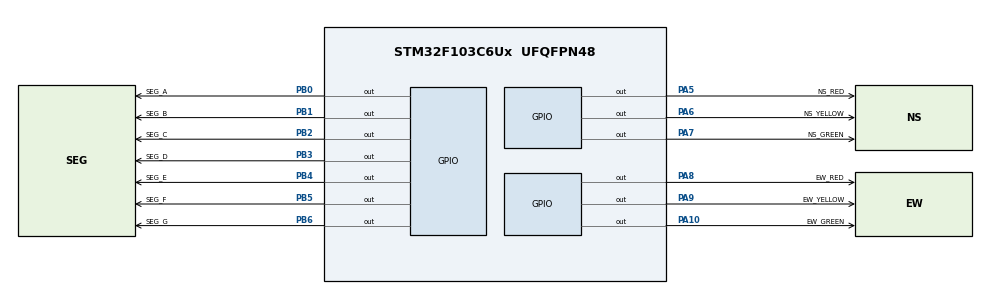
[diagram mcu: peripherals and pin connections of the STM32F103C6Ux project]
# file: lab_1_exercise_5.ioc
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Mcu.Family=STM32F1
Mcu.Name=STM32F103C6Ux
Mcu.Package=UFQFPN48
NVIC.PriorityGroup=NVIC_PRIORITYGROUP_4
ProjectManager.HeapSize=0x200
ProjectManager.StackSize=0x400
ProjectManager.TargetToolchain=STM32CubeIDE
RCC.APB1Freq_Value=8000000
RCC.APB2Freq_Value=8000000
VP_SYS_VS_ND.Mode=No_Debug
board=custom
PA5.GPIO_Label=NS_RED
PA5.PinState=GPIO_PIN_SET
PA5.Signal=GPIO_Output
PA6.GPIO_Label=NS_YELLOW
PA6.PinState=GPIO_PIN_SET
PA6.Signal=GPIO_Output
PA7.GPIO_Label=NS_GREEN
PA7.PinState=GPIO_PIN_SET
PA7.Signal=GPIO_Output
PA8.GPIO_Label=EW_RED
PA8.PinState=GPIO_PIN_SET
PA8.Signal=GPIO_Output
PA9.GPIO_Label=EW_YELLOW
PA9.PinState=GPIO_PIN_SET
PA9.Signal=GPIO_Output
PA10.GPIO_Label=EW_GREEN
PA10.PinState=GPIO_PIN_SET
PA10.Signal=GPIO_Output
PB0.GPIO_Label=SEG_A
PB0.PinState=GPIO_PIN_SET
PB0.Signal=GPIO_Output
PB1.GPIO_Label=SEG_B
PB1.PinState=GPIO_PIN_SET
PB1.Signal=GPIO_Output
PB2.GPIO_Label=SEG_C
PB2.PinState=GPIO_PIN_SET
PB2.Signal=GPIO_Output
PB3.GPIO_Label=SEG_D
PB3.PinState=GPIO_PIN_SET
PB3.Signal=GPIO_Output
PB4.GPIO_Label=SEG_E
PB4.PinState=GPIO_PIN_SET
PB4.Signal=GPIO_Output
PB5.GPIO_Label=SEG_F
PB5.PinState=GPIO_PIN_SET
PB5.Signal=GPIO_Output
PB6.GPIO_Label=SEG_G
PB6.PinState=GPIO_PIN_SET
PB6.Signal=GPIO_Output

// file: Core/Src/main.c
/* USER CODE BEGIN Header */
/**
  ******************************************************************************
  * @file           : main.c
  * @brief          : Main program body
  ******************************************************************************
  * @attention
  *
  * <h2><center>&copy; Copyright (c) 2026 STMicroelectronics.
  * All rights reserved.</center></h2>
  *
  * This software component is licensed by ST under BSD 3-Clause license,
  * the "License"; You may not use this file except in compliance with the
  * License. You may obtain a copy of the License at:
  *                        opensource.org/licenses/BSD-3-Clause
  *
  ******************************************************************************
  */
/* USER CODE END Header */
#include "main.h"

/* USER CODE BEGIN Includes */
#include "lab_app.h"

/* USER CODE END Includes */

void SystemClock_Config(void);
static void MX_GPIO_Init(void);

int main(void)
{

  /* MCU Configuration--------------------------------------------------------*/

  /* Reset of all peripherals, Initializes the Flash interface and the Systick. */
  HAL_Init();

  /* Configure the system clock */
  SystemClock_Config();

  /* Initialize all configured peripherals */
  MX_GPIO_Init();

  /* Infinite loop */
  while (1)
  {
    /* USER CODE BEGIN 3 */
    runExercise();
  }
  /* USER CODE END 3 */
}

void SystemClock_Config(void)
{
  RCC_OscInitTypeDef RCC_OscInitStruct = {0};
  RCC_ClkInitTypeDef RCC_ClkInitStruct = {0};

  /** Initializes the RCC Oscillators according to the specified parameters
  * in the RCC_OscInitTypeDef structure.
  */
  RCC_OscInitStruct.OscillatorType = RCC_OSCILLATORTYPE_HSI;
  RCC_OscInitStruct.HSIState = RCC_HSI_ON;
  RCC_OscInitStruct.HSICalibrationValue = RCC_HSICALIBRATION_DEFAULT;
  RCC_OscInitStruct.PLL.PLLState = RCC_PLL_NONE;
  if (HAL_RCC_OscConfig(&RCC_OscInitStruct) != HAL_OK)
  {
    Error_Handler();
  }
  /** Initializes the CPU, AHB and APB buses clocks
  */
  RCC_ClkInitStruct.ClockType = RCC_CLOCKTYPE_HCLK|RCC_CLOCKTYPE_SYSCLK
                              |RCC_CLOCKTYPE_PCLK1|RCC_CLOCKTYPE_PCLK2;
  RCC_ClkInitStruct.SYSCLKSource = RCC_SYSCLKSOURCE_HSI;
  RCC_ClkInitStruct.AHBCLKDivider = RCC_SYSCLK_DIV1;
  RCC_ClkInitStruct.APB1CLKDivider = RCC_HCLK_DIV1;
  RCC_ClkInitStruct.APB2CLKDivider = RCC_HCLK_DIV1;

  if (HAL_RCC_ClockConfig(&RCC_ClkInitStruct, FLASH_LATENCY_0) != HAL_OK)
  {
    Error_Handler();
  }
}

static void MX_GPIO_Init(void)
{
  GPIO_InitTypeDef GPIO_InitStruct = {0};
  __HAL_RCC_GPIOA_CLK_ENABLE();
  __HAL_RCC_GPIOB_CLK_ENABLE();
  HAL_GPIO_WritePin(GPIOA, TRAFFIC_MASK, GPIO_PIN_SET);
  GPIO_InitStruct.Pin = TRAFFIC_MASK;
  GPIO_InitStruct.Mode = GPIO_MODE_OUTPUT_PP;
  GPIO_InitStruct.Pull = GPIO_NOPULL;
  GPIO_InitStruct.Speed = GPIO_SPEED_FREQ_LOW;
  HAL_GPIO_Init(GPIOA, &GPIO_InitStruct);
  HAL_GPIO_WritePin(GPIOB, SEG_MASK, GPIO_PIN_SET);
  GPIO_InitStruct.Pin = SEG_MASK;
  GPIO_InitStruct.Mode = GPIO_MODE_OUTPUT_PP;
  GPIO_InitStruct.Pull = GPIO_NOPULL;
  GPIO_InitStruct.Speed = GPIO_SPEED_FREQ_LOW;
  HAL_GPIO_Init(GPIOB, &GPIO_InitStruct);
}

void Error_Handler(void)
{
  __disable_irq();
  while (1)
  {
  }
}

/************************ (C) COPYRIGHT STMicroelectronics *****END OF FILE****/
